AUTOSAR XML (schema 00048)
package /HuaweiMDC/PlatformApplication/DiagAgentApplication/Execution
  executable diag_agent
    root sw component prototype diag_agent: application-type=diag_agent
package /HuaweiMDC/PlatformApplication/DiagAgentApplication/SwComponent
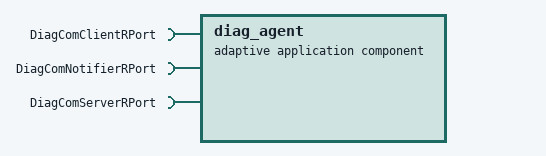
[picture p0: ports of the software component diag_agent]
  adaptive application sw component type diag_agent
    require port DiagComClientRPort
    require port DiagComNotifierRPort
    require port DiagComServerRPort
